# trimsir_me13 register map
Registers are read-only, no defined reset value unless marked. A register's access mark holds for its fields unless they carry their own. Offsets are from the block's base; lines under a group give offsets from that group; [hi:lo] are bit positions; {n}, {i} and the like mark numbered series; 'fields as' and 'values as' point back to an identical list; <NAME> marks a mode.

## Memory map
0x40005400 TRIMSIR size 0x400 — Trim System Initilazation Registers

## TRIMSIR — Trim System Initilazation Registers
Base 0x40005400
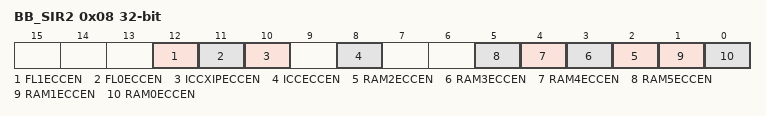
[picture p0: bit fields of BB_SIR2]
0x08 BB_SIR2 — System Init. Configuration Register 2.
  [12] FL1ECCEN — Flash 1 ECC Enable.
  [11] FL0ECCEN — Flash 0 ECC Enable.
  [10] ICCXIPECCEN — ECC ICC XIP Enable.
  [8] ICCECCEN — ECC ICC Enable.
  [n] RAM{n}ECCEN (n=2..5) — ECC System RAM2 Enable.
  [1] RAM1ECCEN — ECC System RAM1 Enable.
  [0] RAM0ECCEN — ECC System RAM0 Enable.
